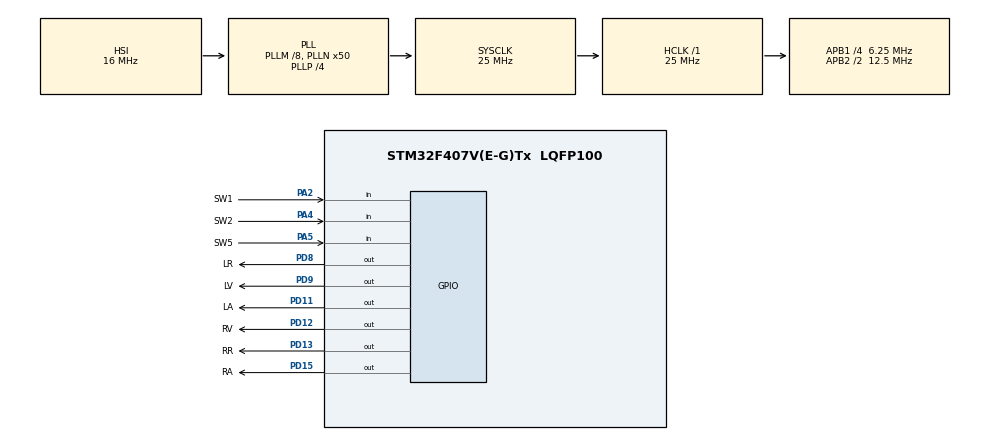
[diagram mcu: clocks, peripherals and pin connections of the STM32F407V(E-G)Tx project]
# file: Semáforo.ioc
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Mcu.Family=STM32F4
Mcu.Name=STM32F407V(E-G)Tx
Mcu.Package=LQFP100
NVIC.PriorityGroup=NVIC_PRIORITYGROUP_0
PA2.GPIO_Label=SW1
PA2.Signal=GPIO_Input
PA4.GPIO_Label=SW2
PA4.Signal=GPIO_Input
PA5.GPIO_Label=SW5
PA5.Signal=GPIO_Input
PD11.GPIO_Label=LA
PD11.Signal=GPIO_Output
PD12.GPIO_Label=RV
PD12.Signal=GPIO_Output
PD13.GPIO_Label=RR
PD13.Signal=GPIO_Output
PD15.GPIO_Label=RA
PD15.Signal=GPIO_Output
PD8.GPIO_Label=LR
PD8.Signal=GPIO_Output
PD9.GPIO_Label=LV
PD9.Signal=GPIO_Output
ProjectManager.HeapSize=0x200
ProjectManager.StackSize=0x400
ProjectManager.TargetToolchain=STM32CubeIDE
RCC.48MHZClocksFreq_Value=14285714.285714285
RCC.AHBFreq_Value=25000000
RCC.APB1CLKDivider=RCC_HCLK_DIV4
RCC.APB1Freq_Value=6250000
RCC.APB1TimFreq_Value=12500000
RCC.APB2CLKDivider=RCC_HCLK_DIV2
RCC.APB2Freq_Value=12500000
RCC.APB2TimFreq_Value=25000000
RCC.CortexFreq_Value=25000000
RCC.HCLKFreq_Value=25000000
RCC.HSE_VALUE=8000000
RCC.HSI_VALUE=16000000
RCC.LSE_VALUE=32768
RCC.PLLM=8
RCC.PLLN=50
RCC.PLLP=RCC_PLLP_DIV4
RCC.PLLQ=7
RCC.SYSCLKFreq_VALUE=25000000
RCC.SYSCLKSource=RCC_SYSCLKSOURCE_PLLCLK
RCC.VCOOutputFreq_Value=100000000
board=STM32F407G-DISC1

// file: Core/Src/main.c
/* USER CODE BEGIN Header */
/**
 ******************************************************************************
 * @file           : main.c
 * @brief          : Main program body
 ******************************************************************************
 * @attention
 *
 * Copyright (c) 2026 STMicroelectronics.
 * All rights reserved.
 *
 * This software is licensed under terms that can be found in the LICENSE file
 * in the root directory of this software component.
 * If no LICENSE file comes with this software, it is provided AS-IS.
 *
 ******************************************************************************
 */
/* USER CODE END Header */
#include "main.h"

/* USER CODE BEGIN Includes */
#include <stdbool.h>
/* USER CODE END Includes */

/* USER CODE BEGIN PD */

#define TREBOTES 20  // intervalo de rebotes en ms
#define TSONDEO 200  // retardo de sondeo en ms
#define TSTOP 1000
#define LED_PORT GPIOD

typedef enum {
	Modo_ltr, Modo_rtl, Modo_blink
} Modo_t;
uint16_t leds[] = {
GPIO_PIN_8, GPIO_PIN_11, GPIO_PIN_9, GPIO_PIN_12, GPIO_PIN_15, GPIO_PIN_13 };
static Modo_t modo_actual = Modo_ltr;

/* USER CODE END PD */

/* USER CODE BEGIN PV */
uint16_t f = 1;
uint16_t n = 1;
/* USER CODE END PV */

void SystemClock_Config(void);
static void MX_GPIO_Init(void);
/* USER CODE BEGIN PFP */
bool VerificarSW1(void);
bool VerificarSW2(void);
bool VerificarSW3(void);
void EjecutarSecuencia(void);
void CambiarModo(void);
/* USER CODE END PFP */

int main(void) {
	HAL_Init();
	SystemClock_Config();
	MX_GPIO_Init();

	while (1) {
		EjecutarSecuencia();
		while (VerificarSW2()) {//Si SW2 esta presionado (activo bajo), entonces cambiamos el tiempo que esta encendido el led.
			n = n + 1;
			f = (n % 3) + 1;
		}
		while (VerificarSW1())
			CambiarModo();
	}
	/* USER CODE END 3 */
}

void SystemClock_Config(void) {
	RCC_OscInitTypeDef RCC_OscInitStruct = { 0 };
	RCC_ClkInitTypeDef RCC_ClkInitStruct = { 0 };

	/** Configure the main internal regulator output voltage
	 */
	__HAL_RCC_PWR_CLK_ENABLE();
	__HAL_PWR_VOLTAGESCALING_CONFIG(PWR_REGULATOR_VOLTAGE_SCALE1);

	/** Initializes the RCC Oscillators according to the specified parameters
	 * in the RCC_OscInitTypeDef structure.
	 */
	RCC_OscInitStruct.OscillatorType = RCC_OSCILLATORTYPE_HSI;
	RCC_OscInitStruct.HSIState = RCC_HSI_ON;
	RCC_OscInitStruct.HSICalibrationValue = RCC_HSICALIBRATION_DEFAULT;
	RCC_OscInitStruct.PLL.PLLState = RCC_PLL_ON;
	RCC_OscInitStruct.PLL.PLLSource = RCC_PLLSOURCE_HSI;
	RCC_OscInitStruct.PLL.PLLM = 8;
	RCC_OscInitStruct.PLL.PLLN = 50;
	RCC_OscInitStruct.PLL.PLLP = RCC_PLLP_DIV4;
	RCC_OscInitStruct.PLL.PLLQ = 7;
	if (HAL_RCC_OscConfig(&RCC_OscInitStruct) != HAL_OK) {
		Error_Handler();
	}

	/** Initializes the CPU, AHB and APB buses clocks
	 */
	RCC_ClkInitStruct.ClockType = RCC_CLOCKTYPE_HCLK | RCC_CLOCKTYPE_SYSCLK
			| RCC_CLOCKTYPE_PCLK1 | RCC_CLOCKTYPE_PCLK2;
	RCC_ClkInitStruct.SYSCLKSource = RCC_SYSCLKSOURCE_PLLCLK;
	RCC_ClkInitStruct.AHBCLKDivider = RCC_SYSCLK_DIV1;
	RCC_ClkInitStruct.APB1CLKDivider = RCC_HCLK_DIV4;
	RCC_ClkInitStruct.APB2CLKDivider = RCC_HCLK_DIV2;

	if (HAL_RCC_ClockConfig(&RCC_ClkInitStruct, FLASH_LATENCY_0) != HAL_OK) {
		Error_Handler();
	}
}

static void MX_GPIO_Init(void) {
	GPIO_InitTypeDef GPIO_InitStruct = { 0 };

	/* GPIO Ports Clock Enable */
	__HAL_RCC_GPIOA_CLK_ENABLE();
	__HAL_RCC_GPIOD_CLK_ENABLE();

	/*Configure GPIO pin Output Level */
	HAL_GPIO_WritePin(GPIOD,
			GPIO_PIN_8 | GPIO_PIN_11 | GPIO_PIN_9 | GPIO_PIN_12 | GPIO_PIN_15
					| GPIO_PIN_13, GPIO_PIN_RESET);

	/*Configure GPIO pins : SW1_Pin SW2_Pin SW5_Pin */
	GPIO_InitStruct.Pin = SW1_Pin | SW2_Pin | SW3_Pin;
	GPIO_InitStruct.Mode = GPIO_MODE_INPUT;
	GPIO_InitStruct.Pull = GPIO_NOPULL;
	HAL_GPIO_Init(GPIOA, &GPIO_InitStruct);

	/*Configure GPIO pins : LR_Pin LV_Pin LA_Pin RV_Pin
	 RR_Pin RA_Pin */
	GPIO_InitStruct.Pin = GPIO_PIN_8 | GPIO_PIN_11 | GPIO_PIN_9 | GPIO_PIN_12
			| GPIO_PIN_15 | GPIO_PIN_13;
	GPIO_InitStruct.Mode = GPIO_MODE_OUTPUT_PP;
	GPIO_InitStruct.Pull = GPIO_NOPULL;
	GPIO_InitStruct.Speed = GPIO_SPEED_FREQ_LOW;
	HAL_GPIO_Init(GPIOD, &GPIO_InitStruct);

}

/* USER CODE BEGIN 4 */

void CambiarModo(void) {
	if (!VerificarSW1()) {
		modo_actual = (modo_actual + 1) % 3;
	}
}

void EjecutarSecuencia(void) {
	switch (modo_actual) {
	case Modo_ltr:
		for (int i = 0; i < 6; i++) {
			HAL_GPIO_WritePin(LED_PORT, leds[i], GPIO_PIN_SET);
			HAL_Delay(TSONDEO * f);
			HAL_GPIO_WritePin(LED_PORT, leds[i], GPIO_PIN_RESET);
		}
		break;

	case Modo_rtl:
		for (int i = 5; i >= 0; i--) {
			HAL_GPIO_WritePin(LED_PORT, leds[i], GPIO_PIN_SET);
			HAL_Delay(TSONDEO * f);
			HAL_GPIO_WritePin(LED_PORT, leds[i], GPIO_PIN_RESET);
		}
		break;

	case Modo_blink:
		// Encender todos
		HAL_GPIO_WritePin(LED_PORT,
		GPIO_PIN_8 | GPIO_PIN_11 | GPIO_PIN_9 |
		GPIO_PIN_12 | GPIO_PIN_15 | GPIO_PIN_13, GPIO_PIN_SET);

		HAL_Delay(TSONDEO * f);

		// Apagar todos
		HAL_GPIO_WritePin(LED_PORT,
		GPIO_PIN_8 | GPIO_PIN_11 | GPIO_PIN_9 |
		GPIO_PIN_12 | GPIO_PIN_15 | GPIO_PIN_13, GPIO_PIN_RESET);

		HAL_Delay(TSONDEO * f);
		break;
	}
}

bool VerificarSW1(void) {
	static GPIO_PinState ultima_lectura_valida = GPIO_PIN_SET; //Boton liberado.
	GPIO_PinState lectura1, lectura2; //Se crean variables para lecturas intermedias.
	bool pedido = false; //No hay pedido hasta que se pulsa el botón.
	lectura1 = HAL_GPIO_ReadPin(SWITCH_GPIO_Port, SW1_Pin); //Se lee el estado del botón SW1.

	if (lectura1 != ultima_lectura_valida) { //Si la lectura del Botón SW1 es distinta de 1 (acordarse que los botones son activo bajo).
		//Se espera un tiempo para filtrar los rebotes.
		HAL_Delay(TREBOTES); //Retardo de TREBOTES ms.
		lectura2 = HAL_GPIO_ReadPin(SWITCH_GPIO_Port, SW1_Pin); //Se lee nuevamente el estado del botón SW1.
		if (lectura2 == lectura1) { //Si ambas lecturas son iguales, se pulso el botón.
			ultima_lectura_valida = lectura2;
		}
		if (ultima_lectura_valida == GPIO_PIN_RESET) //Si la última lectura es igual a 0.
			pedido = true;
	}
	return pedido; // Devuelve a VerificarSW2 si se presiono o no el botón.
}

bool VerificarSW2(void) {
	static GPIO_PinState ultima_lectura_valida = GPIO_PIN_SET; //Boton liberado.
	GPIO_PinState lectura1, lectura2; //Se crean variables para lecturas intermedias.
	bool pedido = false; //No hay pedido hasta que se pulsa el botón.
	lectura1 = HAL_GPIO_ReadPin(SWITCH_GPIO_Port, SW2_Pin); //Se lee el estado del botón SW2.

	if (lectura1 != ultima_lectura_valida) { //Si la lectura del Botón SW2 es distinta de 1 (acordarse que los botones son activo bajo).
		//Se espera un tiempo para filtrar los rebotes.
		HAL_Delay(TREBOTES); //Retardo de TREBOTES ms.
		lectura2 = HAL_GPIO_ReadPin(SWITCH_GPIO_Port, SW2_Pin); //Se lee nuevamente el estado del botón SW2.
		if (lectura2 == lectura1) { //Si ambas lecturas son iguales, se pulso el botón.
			ultima_lectura_valida = lectura2;
		}
		if (ultima_lectura_valida == GPIO_PIN_RESET) //Si la última lectura es igual a 0.
			pedido = true;
	}
	return pedido; // Devuelve a VerificarSW1 si se presiono o no el botón.
}

bool VerificarSW3(void) {
	static GPIO_PinState ultima_lectura_valida = GPIO_PIN_SET; //Boton liberado.
	GPIO_PinState lectura1, lectura2; //Se crean variables para lecturas intermedias.
	bool pedido = false; //No hay pedido hasta que se pulsa el botón.
	lectura1 = HAL_GPIO_ReadPin(SWITCH_GPIO_Port, SW3_Pin); //Se lee el estado del botón SW3.

	if (lectura1 != ultima_lectura_valida) { //Si la lectura del Botón SW3 es distinta de 1 (acordarse que los botones son activo bajo).
		//Se espera un tiempo para filtrar los rebotes.
		HAL_Delay(TREBOTES); //Retardo de TREBOTES ms.
		lectura2 = HAL_GPIO_ReadPin(SWITCH_GPIO_Port, SW3_Pin); //Se lee nuevamente el estado del botón SW3.
		if (lectura2 == lectura1) { //Si ambas lecturas son iguales, se pulso el botón.
			ultima_lectura_valida = lectura2;
		}
		if (ultima_lectura_valida == GPIO_PIN_RESET) //Si la última lectura es igual a 0.
			pedido = true;
	}
	return pedido; // Devuelve a VerificarSW3 si se presiono o no el botón.
}

/* USER CODE END 4 */

void Error_Handler(void) {
	__disable_irq();
	while (1) {
	}
}
